# ATmega329PA device description
Architecture: AVR8; Family: megaAVR
Registers are 8-bit, access not given, no defined reset value unless marked. A register's access mark holds for its fields unless they carry their own. Offsets are from the block's base; [hi:lo] are bit positions; {n}, {i} and the like mark numbered series.

## WDT — Watchdog Timer
Instances: WDT 0x00
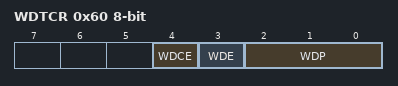
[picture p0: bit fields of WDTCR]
0x60 WDTCR — Watchdog Timer Control Register
  [4] WDCE — Watchdog Change Enable
  [3] WDE — Watch Dog Enable
  [2:0] WDP — Watch Dog Timer Prescaler bits
    0=Oscillator Cycles 16K; 1=Oscillator Cycles 32K; 2=Oscillator Cycles 64K; 3=Oscillator Cycles 128K; 4=Oscillator Cycles 256K; 5=Oscillator Cycles 512K; 6=Oscillator Cycles 1024K; 7=Oscillator Cycles 2048K

## EEPROM
Instances: EEPROM 0x00
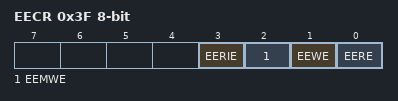
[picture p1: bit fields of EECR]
0x3F EECR — EEPROM Control Register
  [3] EERIE — EEPROM Ready Interrupt Enable
  [2] EEMWE — EEPROM Master Write Enable
  [1] EEWE — EEPROM Write Enable
  [0] EERE — EEPROM Read Enable
0x40 EEDR — EEPROM Data Register
0x41 EEAR 16-bit bits used 9:0 — EEPROM Read/Write Access Bytes

## SPI — Serial Peripheral Interface
Instances: SPI 0x00
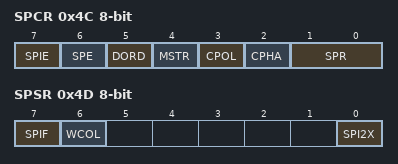
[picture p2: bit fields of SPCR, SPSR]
0x4C SPCR — SPI Control Register
  [7] SPIE — SPI Interrupt Enable
  [6] SPE — SPI Enable
  [5] DORD — Data Order
  [4] MSTR — Master/Slave Select
  [3] CPOL — Clock polarity
  [2] CPHA — Clock Phase
  [1:0] SPR — SPI Clock Rate Selects
    0=fosc/4; 1=fosc/16; 2=fosc/64; 3=fosc/128; 4=fosc/2; 5=fosc/8; 6=fosc/32; 7=fosc/64
0x4D SPSR — SPI Status Register
  [7] SPIF — SPI Interrupt Flag
  [6] WCOL — Write Collision Flag
  [0] SPI2X — Double SPI Speed Bit
0x4E SPDR — SPI Data Register

## PORTA — I/O Port
Instances: PORTA 0x00
0x20 PINA — Port A Input Pins
0x21 DDRA — Port A Data Direction Register
0x22 PORTA — Port A Data Register

## PORTB — I/O Port
Instances: PORTB 0x00
0x23 PINB — Port B Input Pins
0x24 DDRB — Port B Data Direction Register
0x25 PORTB — Port B Data Register

## PORTC — I/O Port
Instances: PORTC 0x00
0x26 PINC — Port C Input Pins
0x27 DDRC — Port C Data Direction Register
0x28 PORTC — Port C Data Register

## PORTD — I/O Port
Instances: PORTD 0x00
0x29 PIND — Port D Input Pins
0x2A DDRD — Port D Data Direction Register
0x2B PORTD — Port D Data Register

## PORTE — I/O Port
Instances: PORTE 0x00
0x2C PINE — Input Pins, Port E
0x2D DDRE — Data Direction Register, Port E
0x2E PORTE — Data Register, Port E

## PORTF — I/O Port
Instances: PORTF 0x00
0x2F PINF — Input Pins, Port F
0x30 DDRF — Data Direction Register, Port F
0x31 PORTF — Data Register, Port F

## PORTG — I/O Port
Instances: PORTG 0x00
0x32 PING bits used 5:0 — Port G Input Pins
0x33 DDRG bits used 4:0 — Port G Data Direction Register
0x34 PORTG bits used 4:0 — Port G Data Register

## AC — Analog Comparator
Instances: AC 0x00
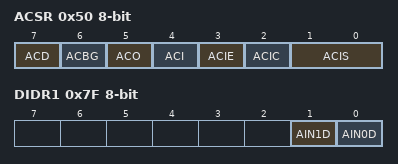
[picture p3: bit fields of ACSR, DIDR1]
0x50 ACSR — Analog Comparator Control And Status Register
  [7] ACD — Analog Comparator Disable
  [6] ACBG — Analog Comparator Bandgap Select
  [5] ACO — Analog Compare Output
  [4] ACI — Analog Comparator Interrupt Flag
  [3] ACIE — Analog Comparator Interrupt Enable
  [2] ACIC — Analog Comparator Input Capture Enable
  [1:0] ACIS — Analog Comparator Interrupt Mode Select bits
    0=Interrupt on Toggle; 2=Interrupt on Falling Edge; 3=Interrupt on Rising Edge
0x7B ADCSRB — ADC Control and Status Register B
  [6] ACME — Analog Comparator Multiplexer Enable
0x7F DIDR1 — Digital Input Disable Register 1
  [1] AIN1D — AIN1 Digital Input Disable
  [0] AIN0D — AIN0 Digital Input Disable

## JTAG — JTAG Interface
Instances: JTAG 0x00
0x51 OCDR — On-Chip Debug Related Register in I/O Memory
0x54 MCUSR — MCU Status Register
  [4] JTRF — JTAG Reset Flag
0x55 MCUCR — MCU Control Register
  [7] JTD — JTAG Interface Disable

## LCD — Liquid Crystal Display
Instances: LCD 0x00
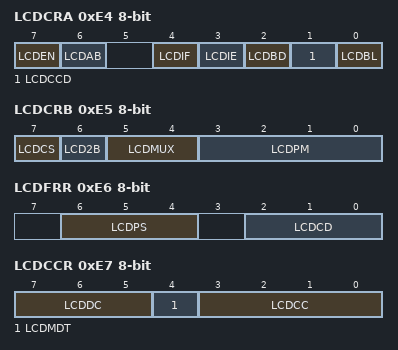
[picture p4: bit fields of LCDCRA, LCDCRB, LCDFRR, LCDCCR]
0xE4 LCDCRA — LCD Control Register A
  [7] LCDEN — LCD Enable
  [6] LCDAB — LCD A or B waveform
  [4] LCDIF — LCD Interrupt Flag
  [3] LCDIE — LCD Interrupt Enable
  [2] LCDBD — LCD Buffer Disable
  [1] LCDCCD — LCD Contrast Control Disable
  [0] LCDBL — LCD Blanking
0xE5 LCDCRB — LCD Control and Status Register B
  [7] LCDCS — LCD CLock Select
  [6] LCD2B — LCD 1/2 Bias Select
  [5:4] LCDMUX — LCD Mux Selects
  [3:0] LCDPM — LCD Port Masks
    0=SEG0:12; 1=SEG0:14; 2=SEG0:15; 3=SEG0:18; 4=SEG0:20; 5=SEG0:22; 6=SEG0:23; 7=SEG0:24; 8=SEG0:26; 9=SEG0:28; 10=SEG0:30; 11=SEG0:32; 12=SEG0:34; 13=SEG0:36; 14=SEG0:38; 15=SEG0:39
0xE6 LCDFRR — LCD Frame Rate Register
  [6:4] LCDPS — LCD Prescaler Selects
    0=ClkLCD/16; 1=ClkLCD/64; 2=ClkLCD/128; 3=ClkLCD/256; 4=ClkLCD/512; 5=ClkLCD/1024; 6=ClkLCD/2048; 7=ClkLCD/4096
  [2:0] LCDCD — LCD Clock Dividers
    {v}={v+1} (v=0..7)
0xE7 LCDCCR — LCD Contrast Control Register
  [7:5] LCDDC — LCD Display Configuration
    0=300us; 1=70us; 2=150us; 3=450us; 4=575us; 5=850us; 6=1150us; 7=50% of LCD clock
  [4] LCDMDT — LCD Maximum Drive Time
  [3:0] LCDCC — LCD Contrast Controls
    0=2.60V; 1=2.65V; 2=2.70V; 3=2.75V; 4=2.80V; 5=2.85V; 6=2.90V; 7=2.95V; 8=3.00V; 9=3.05V; 10=3.10V; 11=3.15V; 12=3.20V; 13=3.25V; 14=3.30V; 15=3.35V
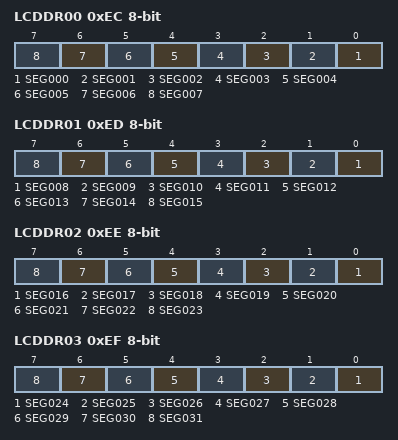
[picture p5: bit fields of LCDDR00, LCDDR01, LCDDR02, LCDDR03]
0xEC LCDDR00 — LCD Data Register 0
  [n] SEG{n:03} (n=0..7) — LCD memory bit segment
0xED LCDDR01 — LCD Data Register 1
  [n-8] SEG{n:03} (n=8..15) — LCD memory bit segment
0xEE LCDDR02 — LCD Data Register 2
  [n-16] SEG{n:03} (n=16..23) — LCD memory bit segment
0xEF LCDDR03 — LCD Data Register 3
  [n-24] SEG{n:03} (n=24..31) — LCD memory bit segment
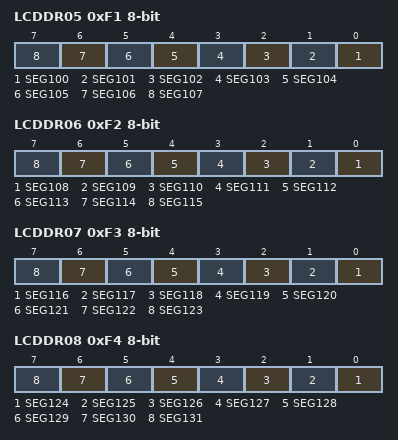
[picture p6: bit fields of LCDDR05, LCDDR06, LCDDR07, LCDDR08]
0xF1 LCDDR05 — LCD Data Register 5
  [n-100] SEG{n} (n=100..107) — LCD memory bit segment
0xF2 LCDDR06 — LCD Data Register 6
  [n-108] SEG{n} (n=108..115) — LCD memory bit segment
0xF3 LCDDR07 — LCD Data Register 7
  [n-116] SEG{n} (n=116..123) — LCD memory bit segment
0xF4 LCDDR08 — LCD Data Register 8
  [n-124] SEG{n} (n=124..131) — LCD memory bit segment
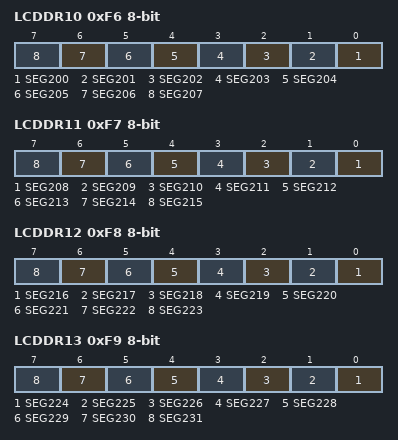
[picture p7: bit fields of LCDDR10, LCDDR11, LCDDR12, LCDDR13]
0xF6 LCDDR10 — LCD Data Register 10
  [n-200] SEG{n} (n=200..207) — LCD memory bit segment
0xF7 LCDDR11 — LCD Data Register 11
  [n-208] SEG{n} (n=208..215) — LCD memory bit segment
0xF8 LCDDR12 — LCD Data Register 12
  [n-216] SEG{n} (n=216..223) — LCD memory bit segment
0xF9 LCDDR13 — LCD Data Register 13
  [n-224] SEG{n} (n=224..231) — LCD memory bit segment
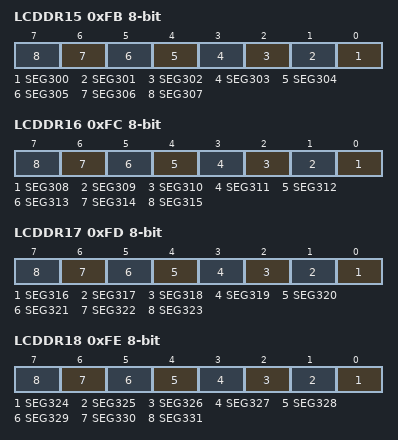
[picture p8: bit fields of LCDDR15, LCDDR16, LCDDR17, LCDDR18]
0xFB LCDDR15 — LCD Data Register 15
  [n-300] SEG{n} (n=300..307) — LCD memory bit segment
0xFC LCDDR16 — LCD Data Register 16
  [n-308] SEG{n} (n=308..315) — LCD memory bit segment
0xFD LCDDR17 — LCD Data Register 17
  [n-316] SEG{n} (n=316..323) — LCD memory bit segment
0xFE LCDDR18 — LCD Data Register 18
  [n-324] SEG{n} (n=324..331) — LCD memory bit segment
